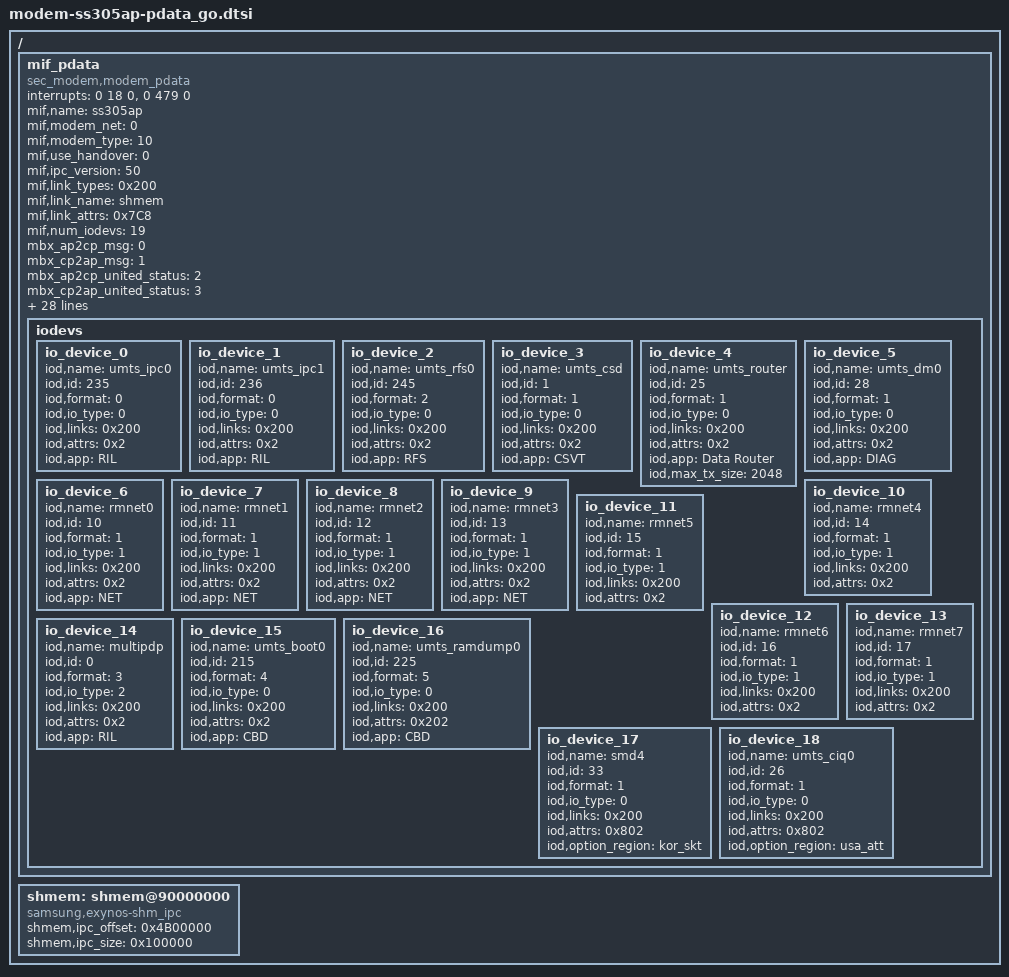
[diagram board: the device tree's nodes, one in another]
/*
 * SAMSUNG UNIVERSAL7570 board device tree source
 *
 * Copyright (c) 2015 Samsung Electronics Co., Ltd.
 *             http://www.samsung.com
 *
 * This program is free software; you can redistribute it and/or modify
 * it under the terms of the GNU General Public License version 2 as
 * published by the Free Software Foundation.
*/

/ {
	/* modem_interface_driver: Samsung Electronics Java */
	mif_pdata {
		compatible = "sec_modem,modem_pdata";
		status = "okay";
		interrupts = <0 18 0>, <0 479 0>;

		/* common pdata */
		mif,name = "ss305ap";
		mif,modem_net = <0>;		/* UMTS_NETWORK */
		mif,modem_type = <10>;		/* SEC_SS310AP */
		mif,use_handover = <0>;		/* not used */
		mif,ipc_version = <50>;		/* SIPC 5.0 */
		mif,link_types = <0x200>;	/* LINKDEV_SHMEM */
		mif,link_name = "shmem";
		mif,link_attrs = <0x7C8>;	/* XMIT_BTDLR(0x400) | DUMP_ALIGNED (0x200) | BOOT_ALIGNED (0x100) | MEM_DUMP (0x80) | MEM_BOOT (0x40) | DPRAM_MAGIC (0x08) */
		mif,num_iodevs = <19>;

		/* mbox pdata */
		mbx_ap2cp_msg = <0>;
		mbx_cp2ap_msg = <1>;
		mbx_ap2cp_united_status = <2>;
		mbx_cp2ap_united_status = <3>;

		mif,int_ap2cp_msg = <0>;
		mif,int_ap2cp_status = <2>;
		mif,int_ap2cp_active = <3>;

		mif,irq_cp2ap_msg = <0>;
		mif,irq_cp2ap_status = <2>;
		mif,irq_cp2ap_active = <3>;
		mif,irq_cp2ap_wake_lock = <8>;

		/* mbox pdata for performance request */
		mbx_cp2ap_dvfsreq = <4>;
		mbx_cp2ap_dvfsreq_mif = <6>;

		mif,irq_cp2ap_perf_req_mif = <6>; /* CP2AP_DVFSREQ_MIF */

		/* CP voltage information */
		mbx_ap2cp_cp_voltage_700 = <5>;
		mbx_ap2cp_cp_voltage_830 = <7>;

		/* mbox pdata for sbi(status bit info) */
		sbi_evs_mode_mask = <0x1>;
		sbi_evs_mode_pos = <7>;
		sbi_lte_active_mask = <0x1>;
		sbi_lte_active_pos = <5>;
		sbi_cp_status_mask = <0xf>;
		sbi_cp_status_pos = <1>;
		sbi_pda_active_mask = <0x1>;
		sbi_pda_active_pos = <5>;
		sbi_ap_status_mask = <0xf>;
		sbi_ap_status_pos = <1>;

		sbi_ds_det_mask = <0x3>;
		sbi_ds_det_pos = <14>;
		sbi_sys_rev_mask = <0xff>;
		sbi_sys_rev_pos = <6>;
		
		sbi_cp_cpu_freq_asv_mask = <0x7>;
		sbi_cp_cpu_freq_asv_pos = <19>;

		iodevs {
			io_device_0 {
				iod,name = "umts_ipc0";
				iod,id = <235>;
				iod,format = <0>;		/* IPC_FMT */
				iod,io_type = <0>;		/* IODEV_MISC */
				iod,links = <0x200>;		/* LINKDEV_SHMEM */
				iod,attrs = <0x2>;		/* ATTR_SIPC5 */
				iod,app = "RIL";
			};
			io_device_1 {
				iod,name = "umts_ipc1";
				iod,id = <236>;
				iod,format = <0>;		/* IPC_FMT */
				iod,io_type = <0>;		/* IODEV_MISC */
				iod,links = <0x200>;		/* LINKDEV_SHMEM */
				iod,attrs = <0x2>;		/* ATTR_SBD_IPC | ATTR_SIPC5 */
				iod,app = "RIL";
			};
			io_device_2 {
				iod,name = "umts_rfs0";
				iod,id = <245>;
				iod,format = <2>;		/* IPC_RFS */
				iod,io_type = <0>;
				iod,links = <0x200>;
				iod,attrs = <0x2>;
				iod,app = "RFS";
			};
			io_device_3 {
				iod,name = "umts_csd";
				iod,id = <1>;
				iod,format = <1>;
				iod,io_type = <0>;
				iod,links = <0x200>;
				iod,attrs = <0x2>;
				iod,app = "CSVT";
			};
			io_device_4 {
				iod,name = "umts_router";
				iod,id = <25>;
				iod,format = <1>;
				iod,io_type = <0>;
				iod,links = <0x200>;
				iod,attrs = <0x2>;
				iod,app = "Data Router";
				iod,max_tx_size = <2048>;
			};
			io_device_5 {
				iod,name = "umts_dm0";
				iod,id = <28>;
				iod,format = <1>;
				iod,io_type = <0>;
				iod,links = <0x200>;
				iod,attrs = <0x2>;
				iod,app = "DIAG";
			};
			io_device_6 {
				iod,name = "rmnet0";
				iod,id = <10>;
				iod,format = <1>;
				iod,io_type = <1>;		/* IODEV_NET */
				iod,links = <0x200>;
				iod,attrs = <0x2>;
				iod,app = "NET";
			};
			io_device_7 {
				iod,name = "rmnet1";
				iod,id = <11>;
				iod,format = <1>;
				iod,io_type = <1>;
				iod,links = <0x200>;
				iod,attrs = <0x2>;
				iod,app = "NET";
						};
			io_device_8 {
				iod,name = "rmnet2";
				iod,id = <12>;
				iod,format = <1>;
				iod,io_type = <1>;
				iod,links = <0x200>;
				iod,attrs = <0x2>;
				iod,app = "NET";
			};
			io_device_9 {
				iod,name = "rmnet3";
				iod,id = <13>;
				iod,format = <1>;
				iod,io_type = <1>;
				iod,links = <0x200>;
				iod,attrs = <0x2>;
				iod,app = "NET";
			};
			io_device_10 {
				iod,name = "rmnet4";
				iod,id = <14>;
				iod,format = <1>;
				iod,io_type = <1>;
				iod,links = <0x200>;
				iod,attrs = <0x2>;
			};
			io_device_11 {
				iod,name = "rmnet5";
				iod,id = <15>;
				iod,format = <1>;
				iod,io_type = <1>;
				iod,links = <0x200>;
				iod,attrs = <0x2>;
			};
			io_device_12 {
				iod,name = "rmnet6";
				iod,id = <16>;
				iod,format = <1>;
				iod,io_type = <1>;
				iod,links = <0x200>;
				iod,attrs = <0x2>;
			};
			io_device_13 {
				iod,name = "rmnet7";
				iod,id = <17>;
				iod,format = <1>;
				iod,io_type = <1>;
				iod,links = <0x200>;
				iod,attrs = <0x2>;
			};
			io_device_14 {
				iod,name = "multipdp";
				iod,id = <0>;
				iod,format = <3>;		/* IPC_MULTI_RAW */
				iod,io_type = <2>;		/* IODEV_DUMMY */
				iod,links = <0x200>;
				iod,attrs = <0x2>;
				iod,app = "RIL";
			};
			io_device_15 {
				iod,name = "umts_boot0";
				iod,id = <215>;
				iod,format = <4>;		/* IPC_BOOT */
				iod,io_type = <0>;
				iod,links = <0x200>;
				iod,attrs = <0x2>;
				iod,app = "CBD";
			};
			io_device_16 {
				iod,name = "umts_ramdump0";
				iod,id = <225>;
				iod,format = <5>;		/* IPC_DUMP */
				iod,io_type = <0>;
				iod,links = <0x200>;
				iod,attrs = <0x202>;		/* ATTR_NO_CHECK_MAXQ | ATTR_SIPC5 */
				iod,app = "CBD";
			};
			io_device_17 {
				iod,name = "smd4";
				iod,id = <33>;
				iod,format = <1>;
				iod,io_type = <0>;
				iod,links = <0x200>;
				iod,attrs = <0x802>;
				iod,option_region = "kor_skt";
			};
			io_device_18 {
				iod,name = "umts_ciq0";
				iod,id = <26>;
				iod,format = <1>;
				iod,io_type = <0>;
				iod,links = <0x200>;
				iod,attrs = <0x802>;
				iod,option_region = "usa_att";
			};
		}; /* end of iodevs */
	}; /* end of mif_pdata */

	shmem: shmem@90000000 {
		compatible = "samsung,exynos-shm_ipc";

		shmem,ipc_offset = <0x4B00000>;
		shmem,ipc_size = <0x100000>;
	};
};
